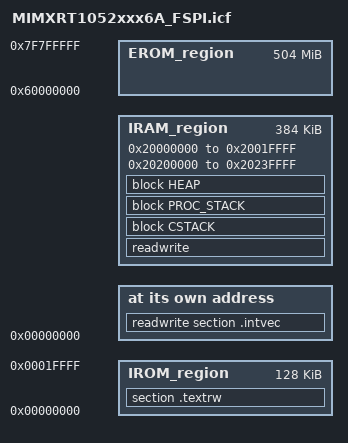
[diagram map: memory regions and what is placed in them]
/*###ICF### Section handled by ICF editor, don't touch! ****/
/*-Editor annotation file-*/
/* IcfEditorFile="$TOOLKIT_DIR$\config\ide\IcfEditor\cortex_v1_4.xml" */
/*-Specials-*/
define symbol __ICFEDIT_intvec_start__ = 0x00000000;
/*-Memory Regions-*/
define symbol __ICFEDIT_region_IROM1_start__ = 0x00000000;
define symbol __ICFEDIT_region_IROM1_end__   = 0x0001FFFF;
define symbol __ICFEDIT_region_IROM2_start__ = 0x0;
define symbol __ICFEDIT_region_IROM2_end__   = 0x0;
define symbol __ICFEDIT_region_EROM1_start__ = 0x60000000;
define symbol __ICFEDIT_region_EROM1_end__   = 0x7F7FFFFF;
define symbol __ICFEDIT_region_EROM2_start__ = 0x0;
define symbol __ICFEDIT_region_EROM2_end__   = 0x0;
define symbol __ICFEDIT_region_EROM3_start__ = 0x0;
define symbol __ICFEDIT_region_EROM3_end__   = 0x0;
define symbol __ICFEDIT_region_IRAM1_start__ = 0x20000000;
define symbol __ICFEDIT_region_IRAM1_end__   = 0x2001FFFF;
define symbol __ICFEDIT_region_IRAM2_start__ = 0x20200000;
define symbol __ICFEDIT_region_IRAM2_end__   = 0x2023FFFF;
define symbol __ICFEDIT_region_ERAM1_start__ = 0x0;
define symbol __ICFEDIT_region_ERAM1_end__   = 0x0;
define symbol __ICFEDIT_region_ERAM2_start__ = 0x0;
define symbol __ICFEDIT_region_ERAM2_end__   = 0x0;
define symbol __ICFEDIT_region_ERAM3_start__ = 0x0;
define symbol __ICFEDIT_region_ERAM3_end__   = 0x0;
/*-Sizes-*/
define symbol __ICFEDIT_size_cstack__     = 0x2000;
define symbol __ICFEDIT_size_proc_stack__ = 0x0;
define symbol __ICFEDIT_size_heap__       = 0x8000;
/**** End of ICF editor section. ###ICF###*/

define memory mem with size = 4G;
define region IROM_region     =   mem:[from __ICFEDIT_region_IROM1_start__ to __ICFEDIT_region_IROM1_end__]
                                | mem:[from __ICFEDIT_region_IROM2_start__ to __ICFEDIT_region_IROM2_end__];
define region EROM_region     =   mem:[from __ICFEDIT_region_EROM1_start__ to __ICFEDIT_region_EROM1_end__]
                                | mem:[from __ICFEDIT_region_EROM2_start__ to __ICFEDIT_region_EROM2_end__]
                                | mem:[from __ICFEDIT_region_EROM3_start__ to __ICFEDIT_region_EROM3_end__];
define region IRAM_region     =   mem:[from __ICFEDIT_region_IRAM1_start__ to __ICFEDIT_region_IRAM1_end__]
                                | mem:[from __ICFEDIT_region_IRAM2_start__ to __ICFEDIT_region_IRAM2_end__];
define region ERAM_region     =   mem:[from __ICFEDIT_region_ERAM1_start__ to __ICFEDIT_region_ERAM1_end__]
                                | mem:[from __ICFEDIT_region_ERAM2_start__ to __ICFEDIT_region_ERAM2_end__]
                                | mem:[from __ICFEDIT_region_ERAM3_start__ to __ICFEDIT_region_ERAM3_end__];

define block CSTACK     with alignment = 8, size = __ICFEDIT_size_cstack__     { };
define block PROC_STACK with alignment = 8, size = __ICFEDIT_size_proc_stack__ { };
define block HEAP       with alignment = 8, size = __ICFEDIT_size_heap__       { };
define block Conf_Data with alignment = 4,  size = 0x1000 {section .conf};
define block VTV_Data  with alignment = 4                 {section .ivt};

initialize by copy { readwrite, section .intvec};
do not initialize  { section .noinit };
if (isdefinedsymbol(__USE_DLIB_PERTHREAD))
{
  // Required in a multi-threaded application
  initialize by copy with packing = none { section __DLIB_PERTHREAD };
}

place at address mem:__ICFEDIT_intvec_start__ { readwrite section .intvec};

place in IROM_region {section .textrw };

place in EROM_region { block app_image with fixed order {block Conf_Data, block VTV_Data, readonly} };
 
place in IRAM_region  { readwrite, block CSTACK, block PROC_STACK, block HEAP  };
